# ESP32-S3 register map
Vendor: ESPRESSIF SYSTEMS (SHANGHAI) CO., LTD.; Series: ESP32 S-Series; File version: 22
CPU: Xtensa LX7 r0p0, little endian, no MPU, FPU, 0 interrupt priority bits
Address unit: 32 bits
Registers are 32-bit, read-write, reset 0x0 unless marked. A register's access mark holds for its fields unless they carry their own. Offsets are from the block's base; [hi:lo] are bit positions; {n}, {i} and the like mark numbered series.

## LCD_CAM — Camera/LCD Controller
Base 0x60041000
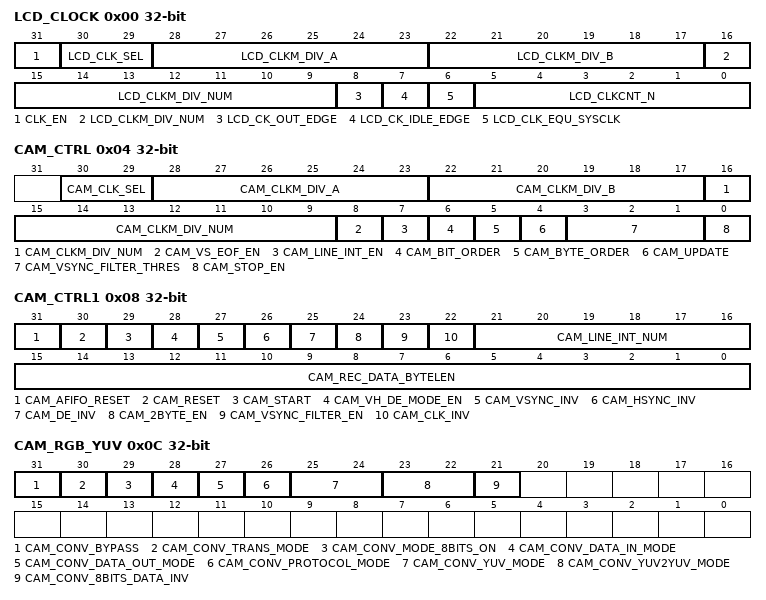
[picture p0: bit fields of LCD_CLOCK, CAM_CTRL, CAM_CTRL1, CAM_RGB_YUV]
0x00 LCD_CLOCK — LCD clock configuration register
  [31] CLK_EN — Set this bit to force enable the clock for all configuration registers. Clock gate is not used.
  [30:29] LCD_CLK_SEL — Select LCD module source clock. 0: clock source is disabled. 1: XTAL_CLK. 2: PLL_D2_CLK. 3: PLL_F160M_CLK.
  [28:23] LCD_CLKM_DIV_A — Fractional clock divider denominator value.
  [22:17] LCD_CLKM_DIV_B — Fractional clock divider numerator value.
  [16:9] LCD_CLKM_DIV_NUM — Integral LCD clock divider value.
  [8] LCD_CK_OUT_EDGE — 1: LCD_PCLK is high in the first half clock cycle. 0: LCD_PCLK is low in the first half clock cycle.
  [7] LCD_CK_IDLE_EDGE — 1: LCD_PCLK line is high in idle. 0: LCD_PCLK line is low in idle.
  [6] LCD_CLK_EQU_SYSCLK — 1: f<SUB>LCD_PCLK</SUB> = f<SUB>LCD_CLK</SUB>. 0: f<SUB>LCD_PCLK</SUB> = f<SUB>LCD_CLK</SUB>/(LCD_CAM_LCD_CLKCNT_N + 1).
  [5:0] LCD_CLKCNT_N — f<SUB>LCD_PCLK</SUB> = f<SUB>LCD_CLK</SUB>/(LCD_CAM_LCD_CLKCNT_N + 1) when LCD_CAM_LCD_CLK_EQU_SYSCLK is 0. Note: this field must not be configured to 0.
0x04 CAM_CTRL — Camera clock configuration register
  [30:29] CAM_CLK_SEL — Select camera module source clock. 0: Clock source is disabled. 1: XTAL_CLK. 2: PLL_D2_CLK. 3: PLL_F160M_CLK.
  [28:23] CAM_CLKM_DIV_A — Fractional clock divider denominator value.
  [22:17] CAM_CLKM_DIV_B — Fractional clock divider numerator value.
  [16:9] CAM_CLKM_DIV_NUM — Integral camera clock divider value.
  [8] CAM_VS_EOF_EN — 1: Enable CAM_VSYNC to generate in_suc_eof. 0: in_suc_eof is controlled by LCD_CAM_CAM_REC_DATA_BYTELEN.
  [7] CAM_LINE_INT_EN — 1: Enable to generate LCD_CAM_CAM_HS_INT. 0: Disable.
  [6] CAM_BIT_ORDER — 1: Change data bit order, change CAM_DATA_in[7:0] to CAM_DATA_in[0:7] in 8-bit mode, and bits[15:0] to bits[0:15] in 16-bit mode. 0: Do not change. % odo[inline]{To XAR: please double check the description of the two bits above.}
  [5] CAM_BYTE_ORDER — 1: Invert data byte order, only valid in 16-bit mode. 0: Do not change.
  [4] CAM_UPDATE — 1: Update camera registers. This bit is cleared by hardware. 0: Do not care.
  [3:1] CAM_VSYNC_FILTER_THRES — Filter threshold value for CAM_VSYNC signal.
  [0] CAM_STOP_EN — Camera stop enable signal, 1: camera stops when GDMA Rx FIFO is full. 0: Do not stop.
0x08 CAM_CTRL1 access per field — Camera control register
  [31] CAM_AFIFO_RESET wo — Camera Async Rx FIFO reset signal.
  [30] CAM_RESET wo — Camera module reset signal.
  [29] CAM_START rw — Camera module start signal.
  [28] CAM_VH_DE_MODE_EN rw — 1: Input control signals are CAM_DE and CAM_HSYNC. CAM_VSYNC is 1. 0: Input control signals are CAM_DE and CAM_VSYNC. CAM_HSYNC and CAM_DE are all 1 at the the same time.
  [27] CAM_VSYNC_INV rw — CAM_VSYNC invert enable signal, valid in high level.
  [26] CAM_HSYNC_INV rw — CAM_HSYNC invert enable signal, valid in high level.
  [25] CAM_DE_INV rw — CAM_DE invert enable signal, valid in high level.
  [24] CAM_2BYTE_EN rw — 1: The width of input data is 16 bits. 0: The width of input data is 8 bits.
  [23] CAM_VSYNC_FILTER_EN rw — 1: Enable CAM_VSYNC filter function. 0: Bypass.
  [22] CAM_CLK_INV rw — 1: Invert the input signal CAM_PCLK. 0: Do not invert.
  [21:16] CAM_LINE_INT_NUM rw — Configure line number. When the number of received lines reaches this value + 1, LCD_CAM_CAM_HS_INT is triggered.
  [15:0] CAM_REC_DATA_BYTELEN rw — Configure camera received data byte length. When the length of received data reaches this value + 1, GDMA in_suc_eof_int is triggered.
0x0C CAM_RGB_YUV — Camera data format conversion register
  [31] CAM_CONV_BYPASS — 0: Bypass converter. 1: Enable converter.
  [30] CAM_CONV_TRANS_MODE — 0: converted to RGB format. 1: converted to YUV format.
  [29] CAM_CONV_MODE_8BITS_ON — 0: 16-bit mode. 1: 8-bit mode.
  [28] CAM_CONV_DATA_IN_MODE — Configure color range for input data. 0: limited color range. 1: full color range.
  [27] CAM_CONV_DATA_OUT_MODE — Configure color range for output data. 0: limited color range. 1: full color range.
  [26] CAM_CONV_PROTOCOL_MODE — 0: BT601. 1: BT709.
  [25:24] CAM_CONV_YUV_MODE — In YUV-to-YUV mode and YUV-to-RGB mode, LCD_CAM_CAM_CONV_YUV_MODE decides the YUV mode of input data. 0: input data is in YUV422 format. 1: input data is in YUV420 format. 2: input data is in YUV411 format. In RGB-to-YUV mode, 0: data is converted to YUV422 format. 1: data is converted to YUV420 format. 2: data is converted to YUV411 format.
  [23:22] CAM_CONV_YUV2YUV_MODE — In YUV-to-YUV mode, 0: data is converted to YUV422 format. 1: data is converted to YUV420 format. 2: data is converted to YUV411 format. 3: disabled. To enable YUV-to-YUV mode, LCD_CAM_CAM_CONV_TRANS_MODE must be set to 1.
  [21] CAM_CONV_8BITS_DATA_INV — Swap every two 8-bit input data. 1: Enabled. 0: Disabled.
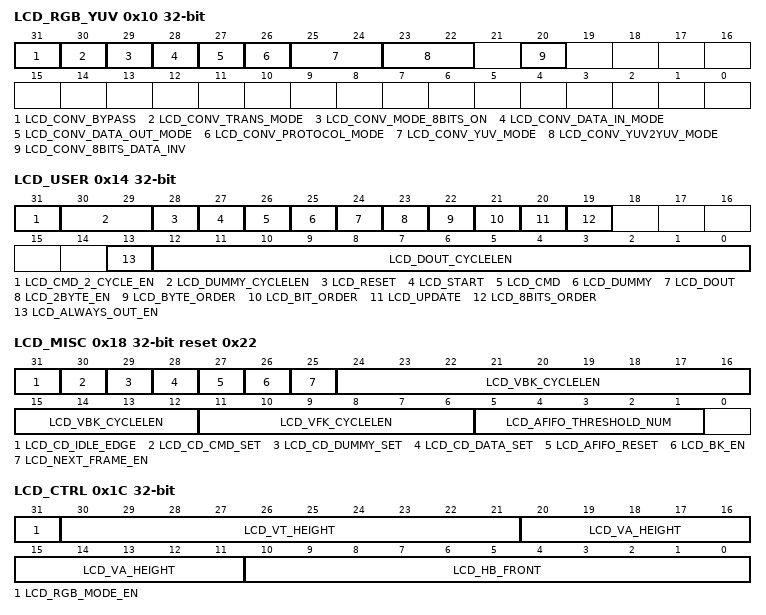
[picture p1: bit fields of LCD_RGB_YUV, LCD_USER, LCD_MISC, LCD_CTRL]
0x10 LCD_RGB_YUV — LCD data format conversion register
  [31] LCD_CONV_BYPASS — 0: Bypass converter. 1: Enable converter.
  [30] LCD_CONV_TRANS_MODE — 0: converted to RGB format. 1: converted to YUV format.
  [29] LCD_CONV_MODE_8BITS_ON — 0: 16-bit mode. 1: 8-bit mode.
  [28] LCD_CONV_DATA_IN_MODE — Configure color range for input data. 0: limited color range. 1: full color range.
  [27] LCD_CONV_DATA_OUT_MODE — Configure color range for output data. 0: limited color range. 1: full color range.
  [26] LCD_CONV_PROTOCOL_MODE — 0: BT601. 1: BT709.
  [25:24] LCD_CONV_YUV_MODE — In YUV-to-YUV mode and YUV-to-RGB mode, LCD_CAM_LCD_CONV_YUV_MODE decides the YUV mode of input data. 0: input data is in YUV422 format. 1: input data is in YUV420 format. 2: input data is in YUV411 format. In RGB-to-YUV mode, 0: data is converted to YUV422 format. 1: data is converted to YUV420 format. 2: data is converted to YUV411 format.
  [23:22] LCD_CONV_YUV2YUV_MODE — In YUV-to-YUV mode, 0: data is converted to YUV422 format. 1: data is converted to YUV420 format. 2: data is converted to YUV411 format. 3: disabled. To enable YUV-to-YUV mode, LCD_CAM_LCD_CONV_TRANS_MODE must be set to 1.
  [20] LCD_CONV_8BITS_DATA_INV — Swap every two 8-bit input data. 1: Enabled. 0: Disabled. % odo[inline]{From jeroen: This is unclear... 'invert' reads as 'negate', but from context it's more likely to be byte-swapping?} %\label{fielddesc:LCDCAMLCDCONVTXTORX}- [LCD_CAM_LCD_CONV_TXTORX] 0: TX-to-RX mode off. 1: TX-to-RX mode on. % odo[inline]{TO XAR: does this TX-to-RX mean the red line (TX FIFO to RX FIFO) in the figure?}
0x14 LCD_USER access per field — LCD user configuration register
  [31] LCD_CMD_2_CYCLE_EN rw — The cycle length of command phase. 1: 2 cycles. 0: 1 cycle.
  [30:29] LCD_DUMMY_CYCLELEN rw — Configure DUMMY cycles. DUMMY cycles = this value + 1.
  [28] LCD_RESET wo — Reset LCD module. % odo[inline]{To XAR: this description seems wrong?}
  [27] LCD_START rw — LCD starts sending data enable signal, valid in high level.
  [26] LCD_CMD rw — 1: Be able to send command in LCD sequence when LCD starts. 0: Disable.
  [25] LCD_DUMMY rw — 1: Enable DUMMY phase in LCD sequence when LCD starts. 0: Disable.
  [24] LCD_DOUT rw — 1: Be able to send data out in LCD sequence when LCD starts. 0: Disable.
  [23] LCD_2BYTE_EN rw — 1: The width of output LCD data is 16 bits. 0: The width of output LCD data is 8 bits.
  [22] LCD_BYTE_ORDER rw — 1: Invert data byte order, only valid in 16-bit mode. 0: Do not invert.
  [21] LCD_BIT_ORDER rw — 1: Change data bit order. Change LCD_DATA_out[7:0] to LCD_DATA_out[0:7] in 8-bit mode, and bits[15:0] to bits[0:15] in 16-bit mode. 0: Do not change.
  [20] LCD_UPDATE rw — 1: Update LCD registers. This bit is cleared by hardware. 0: Do not care.
  [19] LCD_8BITS_ORDER rw — 1: Swap every two data bytes, valid in 8-bit mode. 0: Do not swap.
  [13] LCD_ALWAYS_OUT_EN rw — LCD continues outputting data when LCD is in DOUT phase, till LCD_CAM_LCD_START is cleared or LCD_CAM_LCD_RESET is set.
  [12:0] LCD_DOUT_CYCLELEN rw — Configure the cycles for DOUT phase of LCD module. The cycles = this value + 1.
0x18 LCD_MISC access per field reset 0x22 — LCD MISC configuration register
  [31] LCD_CD_IDLE_EDGE rw — The default value of LCD_CD.
  [30] LCD_CD_CMD_SET rw — 1: LCD_CD = !LCD_CAM_LCD_CD_IDLE_EDGE when LCD is in CMD phase. 0: LCD_CD = LCD_CAM_LCD_CD_IDLE_EDGE.
  [29] LCD_CD_DUMMY_SET rw — 1: LCD_CD = !LCD_CAM_LCD_CD_IDLE_EDGE when LCD is in DUMMY phase. 0: LCD_CD = LCD_CAM_LCD_CD_IDLE_EDGE.
  [28] LCD_CD_DATA_SET rw — 1: LCD_CD = !LCD_CAM_LCD_CD_IDLE_EDGE when LCD is in DOUT phase. 0: LCD_CD = LCD_CAM_LCD_CD_IDLE_EDGE.
  [27] LCD_AFIFO_RESET wo — Async Tx FIFO reset signal.
  [26] LCD_BK_EN rw — 1: Enable blank region when LCD sends data out. 0: No blank region.
  [25] LCD_NEXT_FRAME_EN rw — 1: Send the next frame data when the current frame is sent out. 0: LCD stops when the current frame is sent out.
  [24:12] LCD_VBK_CYCLELEN rw — Configure the hold time cycles in LCD non-RGB mode. Hold cycles expected = this value + 1. %Configure the cycles for vertical back blank region in LCD RGB mode, the cycles = this value + 1. Or configure the hold time cycles in LCD non-RGB mode, the cycles = this value + 1.
  [11:6] LCD_VFK_CYCLELEN rw — Configure the setup cycles in LCD non-RGB mode. Setup cycles expected = this value + 1.
  [5:1] LCD_AFIFO_THRESHOLD_NUM rw — Set the threshold for Async Tx FIFO full event.
0x1C LCD_CTRL — LCD signal configuration register
  [31] LCD_RGB_MODE_EN — 1: Enable RGB mode, and input VSYNC, HSYNC, and DE signals. 0: Disable.
  [30:21] LCD_VT_HEIGHT — It is the vertical total height of a frame.
  [20:11] LCD_VA_HEIGHT — It is the vertical active height of a frame.
  [10:0] LCD_HB_FRONT — It is the horizontal blank front porch of a frame.
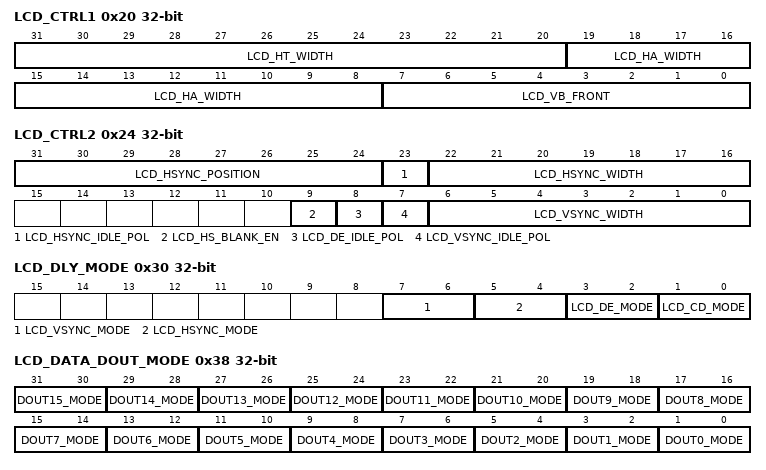
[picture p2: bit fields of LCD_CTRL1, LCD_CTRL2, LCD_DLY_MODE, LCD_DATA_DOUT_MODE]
0x20 LCD_CTRL1 — LCD signal configuration register 1
  [31:20] LCD_HT_WIDTH — It is the horizontal total width of a frame.
  [19:8] LCD_HA_WIDTH — It is the horizontal active width of a frame.
  [7:0] LCD_VB_FRONT — It is the vertical blank front porch of a frame.
0x24 LCD_CTRL2 — LCD signal configuration register 2
  [31:24] LCD_HSYNC_POSITION — It is the position of LCD_HSYNC active pulse in a line.
  [23] LCD_HSYNC_IDLE_POL — It is the idle value of LCD_HSYNC.
  [22:16] LCD_HSYNC_WIDTH — It is the width of LCD_HSYNC active pulse in a line. % odo[inline]{To XAR: postion or width?}
  [9] LCD_HS_BLANK_EN — 1: The pulse of LCD_HSYNC is out in vertical blanking lines in RGB mode. 0: LCD_HSYNC pulse is valid only in active region lines in RGB mode.
  [8] LCD_DE_IDLE_POL — It is the idle value of LCD_DE.
  [7] LCD_VSYNC_IDLE_POL — It is the idle value of LCD_VSYNC.
  [6:0] LCD_VSYNC_WIDTH — It is the width of LCD_VSYNC active pulse in a line. % odo[inline]{To XAR: postition or width?}
0x28 LCD_CMD_VAL — LCD command value configuration register
  [31:0] LCD_CMD_VALUE — The LCD write command value.
0x30 LCD_DLY_MODE — LCD signal delay configuration register
  [7:6] LCD_VSYNC_MODE — The output LCD_VSYNC is delayed by module clock LCD_CLK. 0: output without delay. 1: delayed by the rising edge of LCD_CLK. 2: delay by the falling edge of LCD_CLK.
  [5:4] LCD_HSYNC_MODE — The output LCD_HSYNC is delayed by module clock LCD_CLK. 0: output without delay. 1: delayed by the rising edge of LCD_CLK. 2: delayed by the falling edge of LCD_CLK.
  [3:2] LCD_DE_MODE — The output LCD_DE is delayed by module clock LCD_CLK. 0: output without delay. 1: delayed by the rising edge of LCD_CLK. 2: delayed by the falling edge of LCD_CLK.
  [1:0] LCD_CD_MODE — The output LCD_CD is delayed by module clock LCD_CLK. 0: output without delay. 1: delayed by the rising edge of LCD_CLK. 2: delayed by the falling edge of LCD_CLK.
0x38 LCD_DATA_DOUT_MODE — LCD data delay configuration register
  [2n+1:2n] DOUT{n}_MODE (n=0..15) — The output data bit {n} is delayed by module clock LCD_CLK. 0: output without delay. 1: delayed by the rising edge of LCD_CLK. 2: delayed by the falling edge of LCD_CLK.
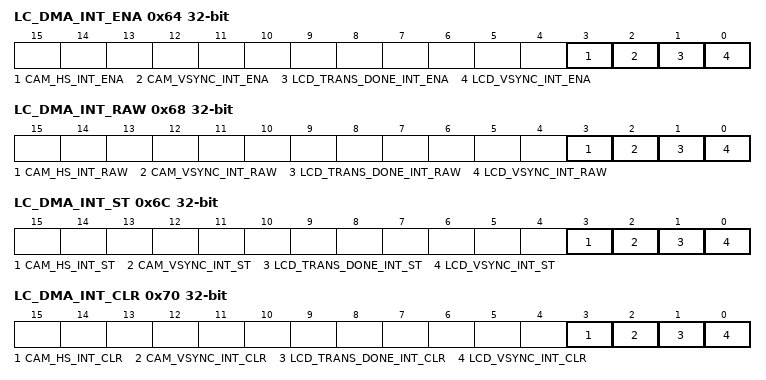
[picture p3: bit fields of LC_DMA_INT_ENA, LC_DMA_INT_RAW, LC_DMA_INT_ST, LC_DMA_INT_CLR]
0x64 LC_DMA_INT_ENA — LCD_CAM GDMA interrupt enable register
  [3] CAM_HS_INT_ENA — The enable bit for LCD_CAM_CAM_HS_INT interrupt.
  [2] CAM_VSYNC_INT_ENA — The enable bit for LCD_CAM_CAM_VSYNC_INT interrupt.
  [1] LCD_TRANS_DONE_INT_ENA — The enable bit for LCD_CAM_LCD_TRANS_DONE_INT interrupt.
  [0] LCD_VSYNC_INT_ENA — The enable bit for LCD_CAM_LCD_VSYNC_INT interrupt.
0x68 LC_DMA_INT_RAW ro — LCD_CAM GDMA raw interrupt status register
  [3] CAM_HS_INT_RAW — The raw bit for LCD_CAM_CAM_HS_INT interrupt.
  [2] CAM_VSYNC_INT_RAW — The raw bit for LCD_CAM_CAM_VSYNC_INT interrupt.
  [1] LCD_TRANS_DONE_INT_RAW — The raw bit for LCD_CAM_LCD_TRANS_DONE_INT interrupt.
  [0] LCD_VSYNC_INT_RAW — The raw bit for LCD_CAM_LCD_VSYNC_INT interrupt.
0x6C LC_DMA_INT_ST ro — LCD_CAM GDMA masked interrupt status register
  [3] CAM_HS_INT_ST — The status bit for LCD_CAM_CAM_HS_INT interrupt.
  [2] CAM_VSYNC_INT_ST — The status bit for LCD_CAM_CAM_VSYNC_INT interrupt.
  [1] LCD_TRANS_DONE_INT_ST — The status bit for LCD_CAM_LCD_TRANS_DONE_INT interrupt.
  [0] LCD_VSYNC_INT_ST — The status bit for LCD_CAM_LCD_VSYNC_INT interrupt.
0x70 LC_DMA_INT_CLR wo — LCD_CAM GDMA interrupt clear register
  [3] CAM_HS_INT_CLR — The clear bit for LCD_CAM_CAM_HS_INT interrupt.
  [2] CAM_VSYNC_INT_CLR — The clear bit for LCD_CAM_CAM_VSYNC_INT interrupt.
  [1] LCD_TRANS_DONE_INT_CLR — The clear bit for LCD_CAM_LCD_TRANS_DONE_INT interrupt.
  [0] LCD_VSYNC_INT_CLR — The clear bit for LCD_CAM_LCD_VSYNC_INT interrupt.
0xFC LC_REG_DATE reset 0x2003020 — Version control register
  [27:0] LC_DATE
